AUTOSAR XML (schema 00049)
package /RB/PT/PCT_DcmSample_Adapter/SwComponentTypes
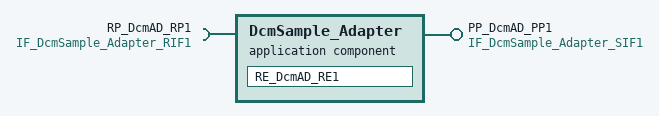
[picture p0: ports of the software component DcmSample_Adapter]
  application sw component type DcmSample_Adapter
    provide port PP_DcmAD_PP1: server-com-spec{operation=CSO_DcmAD_CSO1, queue-length=1}, provided-interface=IF_DcmSample_Adapter_SIF1
    require port RP_DcmAD_RP1: required-interface=IF_DcmSample_Adapter_RIF1
    behavior IB_DcmAD_IB1: data-type-mapping=DTMS_DcmAD_uint8
      operation invoked event OIE_DcmAD_OIE1: start-on-event=RE_DcmAD_RE1, operation=PP_DcmAD_PP1.CSO_DcmAD_CSO1
      runnable RE_DcmAD_RE1: runnable-entity-argument=symbol=REA_DcmAD_RE1_REA1, can-be-invoked-concurrently=true, symbol=DcmSample_Adapter_SRV1
        data-receive-point-by-values:
          access DRP_DcmAD_DRP1: accessed-variable=RP_DcmAD_RP1.VDP_DcmAD_RVDP1
package /RB/PT/PCT_DcmSample_Adapter/PortInterfaces
  sender receiver interface IF_DcmSample_Adapter_RIF1
    data VDP_DcmAD_RVDP1: type=ADT_DcmAD_uint8
  client server interface IF_DcmSample_Adapter_SIF1
    operation CSO_DcmAD_CSO1: possible-error=[E_NOT_OK, E_OK]
      arg APD_DcmAD_CSO1_APD1: type=ADT_DcmAD_uint8, direction=OUT
    error E_OK: error-code=0
    error E_NOT_OK: error-code=1
package /RB/PT/PCT_DcmSample_Adapter/ApplicationDataTypes
  app type ADT_DcmAD_uint8: category=VALUE, sw-calibration-access=READ-ONLY
package /RB/PT/PCT_DcmSample_Adapter/ImplementationDataTypes
  impl type IDT_DcmAD_uint8: implementation-data-type=uint8
package /RB/PT/PCT_DcmSample_Adapter/DataTypeMappingSets
  data type mapping set DTMS_DcmAD_uint8: data-type-map{application-data-type=ADT_DcmAD_uint8, implementation-data-type=IDT_DcmAD_uint8}
package /RB/PT/PCT_DcmSample_Adapter/PortInterfaceMappingSets
  port interface mapping set PIMSet_IF_DcmSample_Adapter_RIF1_IF_DcmSample_Provider_SIF1
    port-interface-mappings:
      variable and parameter interface mapping PIM_VDP_DcmAD_RVDP1_VDP_DcmSP_SVDP1: data-prototype-mapping{first-data-prototype=VDP_DcmAD_RVDP1, second-data-prototype=VDP_DcmSP_SVDP1}
